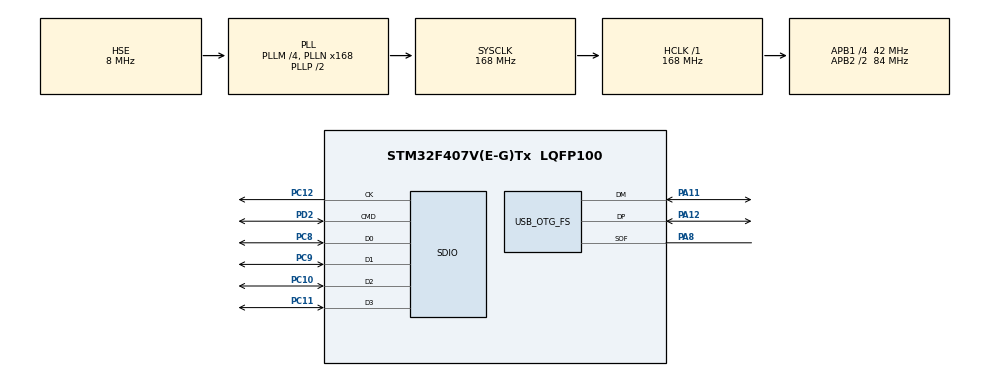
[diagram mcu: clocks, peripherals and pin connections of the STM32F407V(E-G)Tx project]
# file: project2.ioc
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Dma.Request0=SDIO_RX
Dma.Request1=SDIO_TX
Dma.SDIO_RX.0.Direction=DMA_PERIPH_TO_MEMORY
Dma.SDIO_RX.0.FIFOMode=DMA_FIFOMODE_ENABLE
Dma.SDIO_RX.0.FIFOThreshold=DMA_FIFO_THRESHOLD_FULL
Dma.SDIO_RX.0.Instance=DMA2_Stream3
Dma.SDIO_RX.0.MemBurst=DMA_MBURST_INC4
Dma.SDIO_RX.0.MemDataAlignment=DMA_MDATAALIGN_WORD
Dma.SDIO_RX.0.MemInc=DMA_MINC_ENABLE
Dma.SDIO_RX.0.Mode=DMA_PFCTRL
Dma.SDIO_RX.0.PeriphBurst=DMA_PBURST_INC4
Dma.SDIO_RX.0.PeriphDataAlignment=DMA_PDATAALIGN_WORD
Dma.SDIO_RX.0.PeriphInc=DMA_PINC_DISABLE
Dma.SDIO_RX.0.Priority=DMA_PRIORITY_LOW
Dma.SDIO_TX.1.Direction=DMA_MEMORY_TO_PERIPH
Dma.SDIO_TX.1.FIFOMode=DMA_FIFOMODE_ENABLE
Dma.SDIO_TX.1.FIFOThreshold=DMA_FIFO_THRESHOLD_FULL
Dma.SDIO_TX.1.Instance=DMA2_Stream6
Dma.SDIO_TX.1.MemBurst=DMA_MBURST_INC4
Dma.SDIO_TX.1.MemDataAlignment=DMA_MDATAALIGN_WORD
Dma.SDIO_TX.1.MemInc=DMA_MINC_ENABLE
Dma.SDIO_TX.1.Mode=DMA_PFCTRL
Dma.SDIO_TX.1.PeriphBurst=DMA_PBURST_INC4
Dma.SDIO_TX.1.PeriphDataAlignment=DMA_PDATAALIGN_WORD
Dma.SDIO_TX.1.PeriphInc=DMA_PINC_DISABLE
Dma.SDIO_TX.1.Priority=DMA_PRIORITY_LOW
FATFS.USE_DMA_CODE_SD=1
FATFS._USE_LABEL=1
Mcu.Family=STM32F4
Mcu.Name=STM32F407V(E-G)Tx
Mcu.Package=LQFP100
NVIC.DMA2_Stream3_IRQn=true\:0\:0\:false\:false\:true\:false\:true
NVIC.DMA2_Stream6_IRQn=true\:0\:0\:false\:false\:true\:false\:true
NVIC.OTG_FS_IRQn=true\:0\:0\:false\:false\:true\:true\:true
NVIC.PriorityGroup=NVIC_PRIORITYGROUP_4
PA11.Mode=Device_Only
PA11.Signal=USB_OTG_FS_DM
PA12.Mode=Device_Only
PA12.Signal=USB_OTG_FS_DP
PA13.Mode=Trace_Asynchronous_SW
PA13.Signal=SYS_JTMS-SWDIO
PA14.Mode=Trace_Asynchronous_SW
PA14.Signal=SYS_JTCK-SWCLK
PA8.Mode=Activate_SOF_FS
PA8.Signal=USB_OTG_FS_SOF
PB3.Mode=Trace_Asynchronous_SW
PB3.Signal=SYS_JTDO-SWO
PC10.Mode=SD_4_bits_Wide_bus
PC10.Signal=SDIO_D2
PC11.Mode=SD_4_bits_Wide_bus
PC11.Signal=SDIO_D3
PC12.Mode=SD_4_bits_Wide_bus
PC12.Signal=SDIO_CK
PC14-OSC32_IN.Mode=LSE-External-Oscillator
PC14-OSC32_IN.Signal=RCC_OSC32_IN
PC15-OSC32_OUT.Mode=LSE-External-Oscillator
PC15-OSC32_OUT.Signal=RCC_OSC32_OUT
PC8.Mode=SD_4_bits_Wide_bus
PC8.Signal=SDIO_D0
PC9.Mode=SD_4_bits_Wide_bus
PC9.Signal=SDIO_D1
PD2.Mode=SD_4_bits_Wide_bus
PD2.Signal=SDIO_CMD
PH0-OSC_IN.Mode=HSE-External-Oscillator
PH0-OSC_IN.Signal=RCC_OSC_IN
PH1-OSC_OUT.Mode=HSE-External-Oscillator
PH1-OSC_OUT.Signal=RCC_OSC_OUT
ProjectManager.HeapSize=0x200
ProjectManager.StackSize=0x400
ProjectManager.TargetToolchain=STM32CubeIDE
RCC.48MHZClocksFreq_Value=48000000
RCC.AHBFreq_Value=168000000
RCC.APB1CLKDivider=RCC_HCLK_DIV4
RCC.APB1Freq_Value=42000000
RCC.APB1TimFreq_Value=84000000
RCC.APB2CLKDivider=RCC_HCLK_DIV2
RCC.APB2Freq_Value=84000000
RCC.APB2TimFreq_Value=168000000
RCC.CortexFreq_Value=168000000
RCC.HCLKFreq_Value=168000000
RCC.HSE_VALUE=8000000
RCC.HSI_VALUE=16000000
RCC.PLLM=4
RCC.PLLN=168
RCC.PLLQ=7
RCC.SYSCLKFreq_VALUE=168000000
RCC.SYSCLKSource=RCC_SYSCLKSOURCE_PLLCLK
RCC.VCOOutputFreq_Value=336000000
SDIO.ClockDiv=4
USB_DEVICE.CLASS_NAME_FS=AUDIO
USB_DEVICE.USBD_AUDIO_FREQ-AUDIO_FS=48000
USB_DEVICE.VirtualMode-AUDIO_FS=Audio
USB_DEVICE.VirtualModeFS=Audio_FS
USB_OTG_FS.VirtualMode=Device_Only
VP_FATFS_VS_SDIO.Mode=SDIO
VP_USB_DEVICE_VS_USB_DEVICE_AUDIO_FS.Mode=AUDIO_FS
board=custom

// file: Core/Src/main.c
/* USER CODE BEGIN Header */
/**
  ******************************************************************************
  * @file           : main.c
  * @brief          : Main program body
  ******************************************************************************
  * @attention
  *
  * <h2><center>&copy; Copyright (c) 2021 STMicroelectronics.
  * All rights reserved.</center></h2>
  *
  * This software component is licensed by ST under BSD 3-Clause license,
  * the "License"; You may not use this file except in compliance with the
  * License. You may obtain a copy of the License at:
  *                        opensource.org/licenses/BSD-3-Clause
  *
  ******************************************************************************
  */
/* USER CODE END Header */
#include "main.h"
#include "fatfs.h"
#include "usb_device.h"

/* USER CODE BEGIN Includes */
#include "xprintf.h"
/* USER CODE END Includes */

SD_HandleTypeDef hsd;
DMA_HandleTypeDef hdma_sdio_rx;
DMA_HandleTypeDef hdma_sdio_tx;

void SystemClock_Config(void);
static void MX_GPIO_Init(void);
static void MX_DMA_Init(void);
static void MX_SDIO_SD_Init(void);

int main(void)
{
  /* USER CODE BEGIN 1 */
	xdev_out(ITM_SendChar);
	  	xprintf("Starting up\n");

  /* USER CODE END 1 */

  /* MCU Configuration--------------------------------------------------------*/

  /* Reset of all peripherals, Initializes the Flash interface and the Systick. */
  HAL_Init();

  /* Configure the system clock */
  SystemClock_Config();

  /* Initialize all configured peripherals */
  MX_GPIO_Init();
  MX_DMA_Init();
  MX_SDIO_SD_Init();
  MX_FATFS_Init();

  //processMusicManager();
  MMInit();

  MX_USB_DEVICE_Init();
  /* USER CODE BEGIN 2 */

  transportInit();

  //FLAC implementation
  //StartTaskFS(1);

  //Wave implementation
//WavInit();
//WavPlayNonBlocking();
//WavPlayBlocking();

  /* USER CODE END 2 */

  /* Infinite loop */
  /* USER CODE BEGIN WHILE */
  while (1)
  {
	 // WavPlayNonBlocking();

	  processTransport();
	  processTasks();
	  processMusicManager();
    /* USER CODE END WHILE */

  }
}

void SystemClock_Config(void)
{
  RCC_OscInitTypeDef RCC_OscInitStruct = {0};
  RCC_ClkInitTypeDef RCC_ClkInitStruct = {0};

  /** Configure the main internal regulator output voltage
  */
  __HAL_RCC_PWR_CLK_ENABLE();
  __HAL_PWR_VOLTAGESCALING_CONFIG(PWR_REGULATOR_VOLTAGE_SCALE1);
  /** Initializes the RCC Oscillators according to the specified parameters
  * in the RCC_OscInitTypeDef structure.
  */
  RCC_OscInitStruct.OscillatorType = RCC_OSCILLATORTYPE_HSE;
  RCC_OscInitStruct.HSEState = RCC_HSE_ON;
  RCC_OscInitStruct.PLL.PLLState = RCC_PLL_ON;
  RCC_OscInitStruct.PLL.PLLSource = RCC_PLLSOURCE_HSE;
  RCC_OscInitStruct.PLL.PLLM = 4;
  RCC_OscInitStruct.PLL.PLLN = 168;
  RCC_OscInitStruct.PLL.PLLP = RCC_PLLP_DIV2;
  RCC_OscInitStruct.PLL.PLLQ = 7;
  if (HAL_RCC_OscConfig(&RCC_OscInitStruct) != HAL_OK)
  {
    Error_Handler();
  }
  /** Initializes the CPU, AHB and APB buses clocks
  */
  RCC_ClkInitStruct.ClockType = RCC_CLOCKTYPE_HCLK|RCC_CLOCKTYPE_SYSCLK
                              |RCC_CLOCKTYPE_PCLK1|RCC_CLOCKTYPE_PCLK2;
  RCC_ClkInitStruct.SYSCLKSource = RCC_SYSCLKSOURCE_PLLCLK;
  RCC_ClkInitStruct.AHBCLKDivider = RCC_SYSCLK_DIV1;
  RCC_ClkInitStruct.APB1CLKDivider = RCC_HCLK_DIV4;
  RCC_ClkInitStruct.APB2CLKDivider = RCC_HCLK_DIV2;

  if (HAL_RCC_ClockConfig(&RCC_ClkInitStruct, FLASH_LATENCY_5) != HAL_OK)
  {
    Error_Handler();
  }
}

static void MX_SDIO_SD_Init(void)
{

  hsd.Instance = SDIO;
  hsd.Init.ClockEdge = SDIO_CLOCK_EDGE_RISING;
  hsd.Init.ClockBypass = SDIO_CLOCK_BYPASS_DISABLE;
  hsd.Init.ClockPowerSave = SDIO_CLOCK_POWER_SAVE_DISABLE;
  hsd.Init.BusWide = SDIO_BUS_WIDE_1B;
  hsd.Init.HardwareFlowControl = SDIO_HARDWARE_FLOW_CONTROL_DISABLE;
  hsd.Init.ClockDiv = 4;

}

static void MX_DMA_Init(void)
{

  /* DMA controller clock enable */
  __HAL_RCC_DMA2_CLK_ENABLE();

  /* DMA interrupt init */
  /* DMA2_Stream3_IRQn interrupt configuration */
  HAL_NVIC_SetPriority(DMA2_Stream3_IRQn, 0, 0);
  HAL_NVIC_EnableIRQ(DMA2_Stream3_IRQn);
  /* DMA2_Stream6_IRQn interrupt configuration */
  HAL_NVIC_SetPriority(DMA2_Stream6_IRQn, 0, 0);
  HAL_NVIC_EnableIRQ(DMA2_Stream6_IRQn);

}

static void MX_GPIO_Init(void)
{

  /* GPIO Ports Clock Enable */
  __HAL_RCC_GPIOC_CLK_ENABLE();
  __HAL_RCC_GPIOH_CLK_ENABLE();
  __HAL_RCC_GPIOA_CLK_ENABLE();
  __HAL_RCC_GPIOD_CLK_ENABLE();
  __HAL_RCC_GPIOB_CLK_ENABLE();

}

void Error_Handler(void)
{
  __disable_irq();
  while (1)
  {
  }
}

/************************ (C) COPYRIGHT STMicroelectronics *****END OF FILE****/
